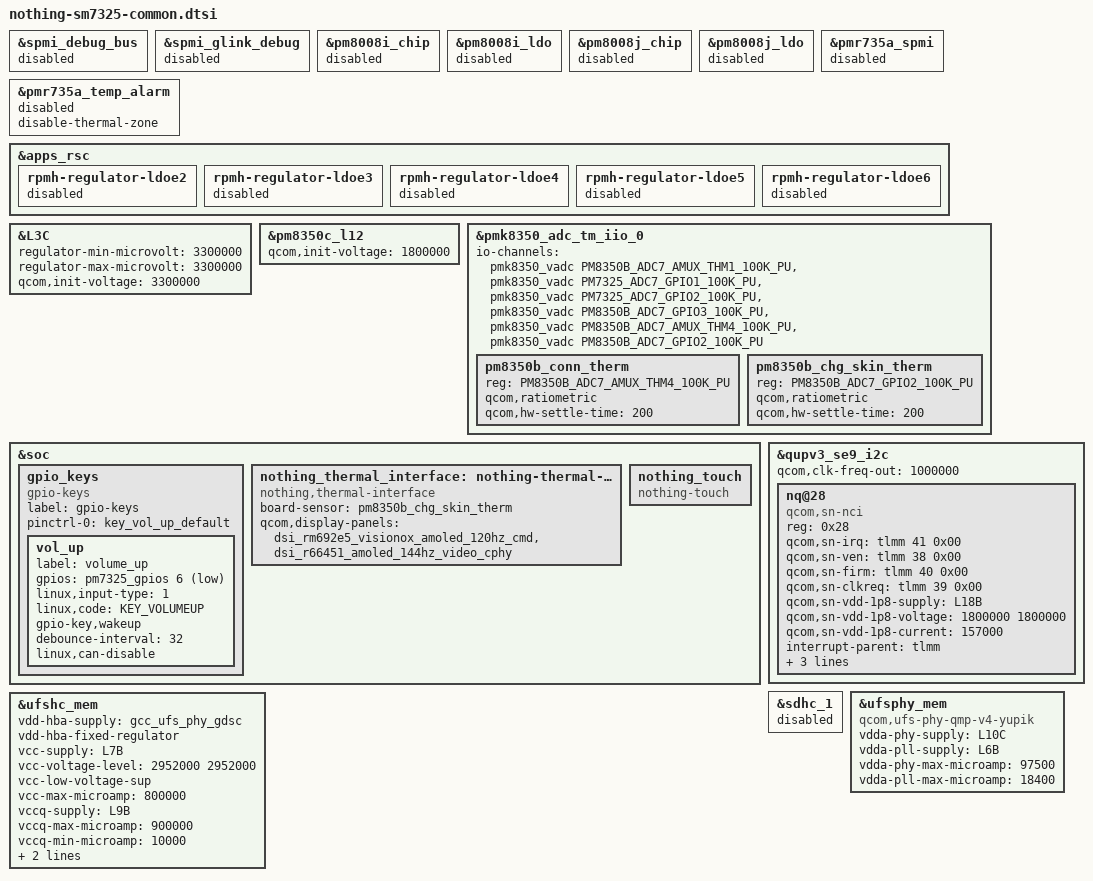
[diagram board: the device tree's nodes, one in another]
#include <dt-bindings/gpio/gpio.h>
#include <dt-bindings/input/input.h>
#include <dt-bindings/iio/qcom,spmi-adc7-pm7325.h>
#include <dt-bindings/iio/qcom,spmi-adc7-pm8350b.h>

&spmi_debug_bus {
	status = "disabled";
};

&spmi_glink_debug {
	status = "disabled";
};

/*
 * pm8008 PMIC and LDO are not used by Nothing SM7325 platform
 */
&pm8008i_chip {
	status = "disabled";
};

&pm8008i_ldo {
	status = "disabled";
};

&pm8008j_chip {
	status = "disabled";
};

&pm8008j_ldo {
	status = "disabled";
};

/*
 * PMR735a specific diff for Nothing SM7325 platform
 */
&pmr735a_spmi {
	status = "disabled";
};

&pmr735a_temp_alarm {
	disable-thermal-zone;
	status = "disabled";
};

&apps_rsc {
	rpmh-regulator-ldoe2 {
		status = "disabled";
	};

	rpmh-regulator-ldoe3 {
		status = "disabled";
	};

	rpmh-regulator-ldoe4 {
		status = "disabled";
	};

	rpmh-regulator-ldoe5 {
		status = "disabled";
	};

	rpmh-regulator-ldoe6 {
		status = "disabled";
	};
};

/*
 * PM8350C devices specific diff for Nothing SM7325 platform
 */
&L3C {
	regulator-min-microvolt = <3300000>;
	regulator-max-microvolt = <3300000>;
	qcom,init-voltage = <3300000>;
};

&pm8350c_l12 {
	qcom,init-voltage = <1800000>;
};

/*
 * PMK8350 specific diff for Nothing SM7325 platform
 */
&pmk8350_adc_tm_iio_0 {
	io-channels = <&pmk8350_vadc PM8350B_ADC7_AMUX_THM1_100K_PU>,
		      <&pmk8350_vadc PM7325_ADC7_GPIO1_100K_PU>,
		      <&pmk8350_vadc PM7325_ADC7_GPIO2_100K_PU>,
		      <&pmk8350_vadc PM8350B_ADC7_GPIO3_100K_PU>,
		      <&pmk8350_vadc PM8350B_ADC7_AMUX_THM4_100K_PU>,
		      <&pmk8350_vadc PM8350B_ADC7_GPIO2_100K_PU>;

	pm8350b_conn_therm {
		reg = <PM8350B_ADC7_AMUX_THM4_100K_PU>;
		qcom,ratiometric;
		qcom,hw-settle-time = <200>;
	};

	pm8350b_chg_skin_therm {
		reg = <PM8350B_ADC7_GPIO2_100K_PU>;
		qcom,ratiometric;
		qcom,hw-settle-time = <200>;
	};
};

&soc {
	gpio_keys {
		compatible = "gpio-keys";
		label = "gpio-keys";

		pinctrl-names = "default";
		pinctrl-0 = <&key_vol_up_default>;

		vol_up {
			label = "volume_up";
			gpios = <&pm7325_gpios 6 GPIO_ACTIVE_LOW>;
			linux,input-type = <1>;
			linux,code = <KEY_VOLUMEUP>;
			gpio-key,wakeup;
			debounce-interval = <32>;
			linux,can-disable;
		};
	};

	nothing_thermal_interface: nothing-thermal-interface {
		compatible = "nothing,thermal-interface";
		board-sensor = "pm8350b_chg_skin_therm";
		qcom,display-panels = <&dsi_rm692e5_visionox_amoled_120hz_cmd
				       &dsi_r66451_amoled_144hz_video_cphy>;
	};

	nothing_touch {
		compatible = "nothing-touch";
		status = "okay";
	};
};

&qupv3_se9_i2c {
	status = "okay";
	qcom,clk-freq-out = <1000000>;
	#address-cells = <1>;
	#size-cells = <0>;

	nq@28 {
		compatible = "qcom,sn-nci";
		reg = <0x28>;
		qcom,sn-irq    = <&tlmm 41 0x00>;
		qcom,sn-ven    = <&tlmm 38 0x00>;
		qcom,sn-firm   = <&tlmm 40 0x00>;
		qcom,sn-clkreq = <&tlmm 39 0x00>;
		qcom,sn-vdd-1p8-supply = <&L18B>;
		qcom,sn-vdd-1p8-voltage = <1800000 1800000>;
		qcom,sn-vdd-1p8-current = <157000>;
		interrupt-parent = <&tlmm>;
		interrupts = <41 0>;
		interrupt-names = "nfc_irq";
		pinctrl-names = "nfc_active", "nfc_suspend";
		pinctrl-0 = <&nfc_int_active &nfc_enable_active>;
		pinctrl-1 = <&nfc_int_suspend &nfc_enable_suspend>;
		status = "okay";
	};
};

&sdhc_1 {
	status = "disabled";
};

&ufsphy_mem {
	compatible = "qcom,ufs-phy-qmp-v4-yupik";

	vdda-phy-supply = <&L10C>;
	vdda-pll-supply = <&L6B>;
	vdda-phy-max-microamp = <97500>;
	vdda-pll-max-microamp = <18400>;

	status = "okay";
};

&ufshc_mem {
	vdd-hba-supply = <&gcc_ufs_phy_gdsc>;
	vdd-hba-fixed-regulator;

	vcc-supply = <&L7B>;
	vcc-voltage-level = <2952000 2952000>;
	vcc-low-voltage-sup;
	vcc-max-microamp = <800000>;

	vccq-supply = <&L9B>;
	vccq-max-microamp = <900000>;
	vccq-min-microamp = <10000>;

	qcom,vddp-ref-clk-supply = <&L9B>;
	qcom,vddp-ref-clk-max-microamp = <100>;

	status = "okay";
};
